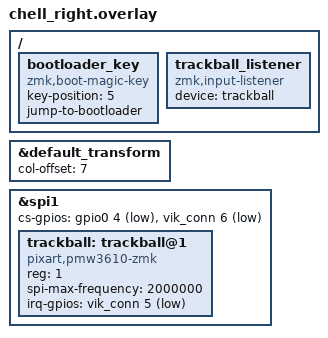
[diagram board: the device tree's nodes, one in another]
#include "chell.dtsi"

/ {
    bootloader_key: bootloader_key {
        compatible = "zmk,boot-magic-key";
        key-position = <5>;
        jump-to-bootloader;
    };
};

&default_transform {
    col-offset = <7>;
};

// PMW3610 trackball via VIK connector SPI bus.
// The shifter (595@0) is already defined in chell.dtsi at reg <0>.
// The trackball is at reg <1>, using VIK connector CS line (gpio0 4 is
// already the bus CS from chell.dtsi, vik_conn 6 is the trackball CS).
&spi1 {
    cs-gpios = <&gpio0 4 GPIO_ACTIVE_LOW>, <&vik_conn 6 GPIO_ACTIVE_LOW>;

    trackball: trackball@1 {
        status = "okay";
        compatible = "pixart,pmw3610-zmk";
        reg = <1>;
        spi-max-frequency = <2000000>;
        irq-gpios = <&vik_conn 5 (GPIO_ACTIVE_LOW | GPIO_PULL_UP)>;
    };
};

/ {
    trackball_listener {
        compatible = "zmk,input-listener";
        device = <&trackball>;
    };
};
